# AT32F421xx_v2 register map
Vendor: Keil; Series: AT32F421; File version: 1.0
CPU: CM4 r0p1, little endian, no MPU, FPU, 4 interrupt priority bits
Registers are 32-bit, read-write, reset 0x0 unless marked. A register's access mark holds for its fields unless they carry their own. Offsets are from the block's base; [hi:lo] are bit positions.

## USART1 — Universal synchronous asynchronous receiver transmitter
Base 0x40013800
Same registers: USART2 0x40004400
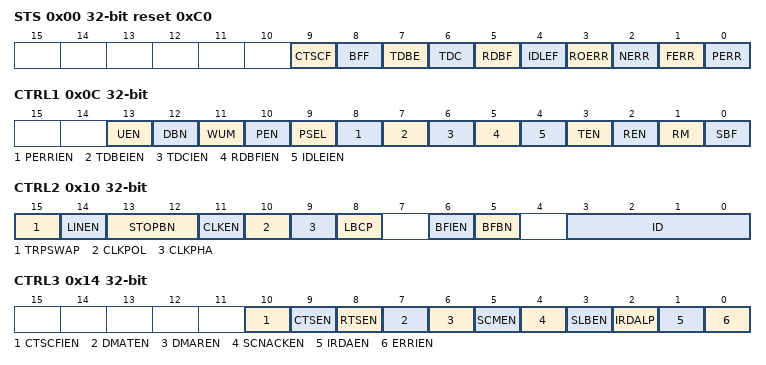
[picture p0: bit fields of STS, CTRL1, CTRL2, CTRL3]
0x00 STS reset 0xC0 — Status register
  [9] CTSCF — CTS change flag
  [8] BFF — Break frame flag
  [7] TDBE ro — Transmit data buffer empty
  [6] TDC — Transmit data complete
  [5] RDBF — Receive data buffer full
  [4] IDLEF ro — IDLE flag
  [3] ROERR ro — Receiver overflow error
  [2] NERR ro — Noise error
  [1] FERR ro — Framing error
  [0] PERR ro — Parity error
0x04 DT — Data register
  [8:0] DT — Data value
0x08 BAUDR — Baud rate register
  [15:0] DIV — Division
0x0C CTRL1 — Control register 1
  [13] UEN — USART enable
  [12] DBN — Data bit num
  [11] WUM — Wake up mode
  [10] PEN — Parity enable
  [9] PSEL — Parity selection
  [8] PERRIEN — PERR interrupt enable
  [7] TDBEIEN — TDBE interrupt enable
  [6] TDCIEN — TDC interrupt enable
  [5] RDBFIEN — RDBF interrupt enable
  [4] IDLEIEN — IDLE interrupt enable
  [3] TEN — Transmitter enable
  [2] REN — Receiver enable
  [1] RM — Receiver mute
  [0] SBF — Send break frame
0x10 CTRL2 — Control register 2
  [15] TRPSWAP — Transmit receive pin swap
  [14] LINEN — LIN mode enable
  [13:12] STOPBN — STOP bit num
  [11] CLKEN — Clock enable
  [10] CLKPOL — Clock polarity
  [9] CLKPHA — Clock phase
  [8] LBCP — Last bit clock pulse
  [6] BFIEN — Break frame interrupt enable
  [5] BFBN — Break frame bit num
  [3:0] ID — USART identification
0x14 CTRL3 — Control register 3
  [10] CTSCFIEN — CTSCF interrupt enable
  [9] CTSEN — CTS enable
  [8] RTSEN — RTS enable
  [7] DMATEN — DMA transmitter enable
  [6] DMAREN — DMA receiver enable
  [5] SCMEN — Smartcard mode enable
  [4] SCNACKEN — Smartcard NACK enable
  [3] SLBEN — Single line bidirectional half-duplex enable
  [2] IRDALP — IrDA low-power mode
  [1] IRDAEN — IrDA enable
  [0] ERRIEN — Error interrupt enable
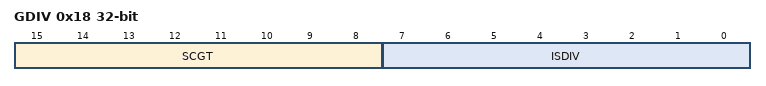
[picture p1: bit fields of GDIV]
0x18 GDIV — Guard time and division register
  [15:8] SCGT — Smart card guard time value
  [7:0] ISDIV — IrDA/smartcard division value

## CMP — Comparator
Base 0x4001001C
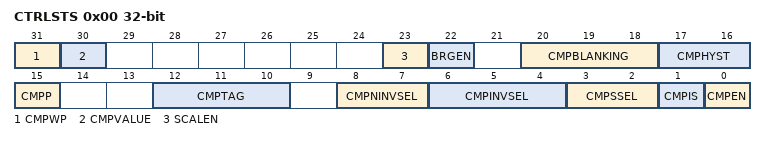
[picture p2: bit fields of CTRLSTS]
0x00 CTRLSTS — CMP control/status register
  [31] CMPWP — Comparator write protect
  [30] CMPVALUE ro — Comparator output value
  [23] SCALEN — Comparator scalen
  [22] BRGEN — Comparator brgen
  [20:18] CMPBLANKING — Comparator blanking
  [17:16] CMPHYST — Comparator hysteresis
  [15] CMPP — Comparator polarity
  [12:10] CMPTAG — Comparator output target
  [8:7] CMPNINVSEL — Comparator non-inverting input selection
  [6:4] CMPINVSEL — Comparator inverting selection
  [3:2] CMPSSEL — Comparator speed selection
  [1] CMPIS — Comparator input shift
  [0] CMPEN — Comparator enable bit
0x08 G_FILTER_EN
  [0] GFE — Glitch filter enable
0x0C HIGH_PULSE
  [5:0] H_PULSE_CNT — High pulse Count
0x10 LOW_PULSE
  [5:0] L_PULSE_CNT — Low pulse Count

## DEBUG — Debug support
Base 0xE0042000
0x00 IDCODE ro — DEBUG_IDCODE
  [31:0] PID
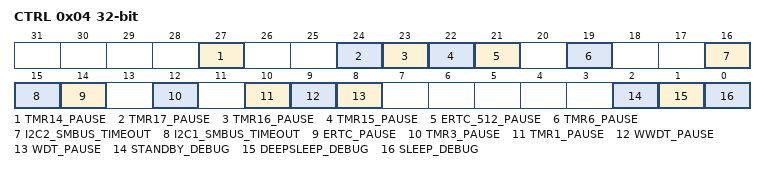
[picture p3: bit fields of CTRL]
0x04 CTRL — DEBUG_CTRL
  [27] TMR14_PAUSE, [24] TMR17_PAUSE, [23] TMR16_PAUSE, [22] TMR15_PAUSE, [21] ERTC_512_PAUSE, [19] TMR6_PAUSE, [16] I2C2_SMBUS_TIMEOUT, [15] I2C1_SMBUS_TIMEOUT, [14] ERTC_PAUSE, [12] TMR3_PAUSE, [10] TMR1_PAUSE, [9] WWDT_PAUSE, [8] WDT_PAUSE, [2] STANDBY_DEBUG, [1] DEEPSLEEP_DEBUG, [0] SLEEP_DEBUG

## CRC — CRC calculation unit
Base 0x40023000
0x00 DT reset 0xFFFFFFFF — Data register
  [31:0] DT — Data Register
0x04 CDT — Common data register
  [7:0] CDT — Common Data
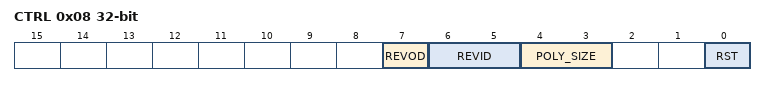
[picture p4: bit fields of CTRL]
0x08 CTRL — Control register
  [7] REVOD — Reverse output data
  [6:5] REVID — Reverse input data
  [4:3] POLY_SIZE — Polynomial size
  [0] RST — Reset bit
0x10 IDT reset 0xFFFFFFFF — Initial data register
  [31:0] IDT — Initial Data
0x14 POLY reset 0x4C11DB7 — Polynomial coefficient register
  [31:0] POLY — polynomial coefficient

## Notices in the file
Copyright (C) 2012-2014 ARM Limited. All rights reserved.
Purpose: System Viewer Description (SVD) Example (Schema Version 1.1)
This is a description of a none-existent and incomplete device
for demonstration purposes only.
Redistribution and use in source and binary forms, with or without
modification, are permitted provided that the following conditions are met:
- Redistributions of source code must retain the above copyright
notice, this list of conditions and the following disclaimer.
- Redistributions in binary form must reproduce the above copyright
notice, this list of conditions and the following disclaimer in the
documentation and/or other materials provided with the distribution.
- Neither the name of ARM nor the names of its contributors may be used
to endorse or promote products derived from this software without
specific prior written permission.
THIS SOFTWARE IS PROVIDED BY THE COPYRIGHT HOLDERS AND CONTRIBUTORS "AS IS"
AND ANY EXPRESS OR IMPLIED WARRANTIES, INCLUDING, BUT NOT LIMITED TO, THE
IMPLIED WARRANTIES OF MERCHANTABILITY AND FITNESS FOR A PARTICULAR PURPOSE
ARE DISCLAIMED. IN NO EVENT SHALL COPYRIGHT HOLDERS AND CONTRIBUTORS BE
LIABLE FOR ANY DIRECT, INDIRECT, INCIDENTAL, SPECIAL, EXEMPLARY, OR
CONSEQUENTIAL DAMAGES (INCLUDING, BUT NOT LIMITED TO, PROCUREMENT OF
SUBSTITUTE GOODS OR SERVICES; LOSS OF USE, DATA, OR PROFITS; OR BUSINESS
INTERRUPTION) HOWEVER CAUSED AND ON ANY THEORY OF LIABILITY, WHETHER IN
CONTRACT, STRICT LIABILITY, OR TORT (INCLUDING NEGLIGENCE OR OTHERWISE)
ARISING IN ANY WAY OUT OF THE USE OF THIS SOFTWARE, EVEN IF ADVISED OF THE
POSSIBILITY OF SUCH DAMAGE.
